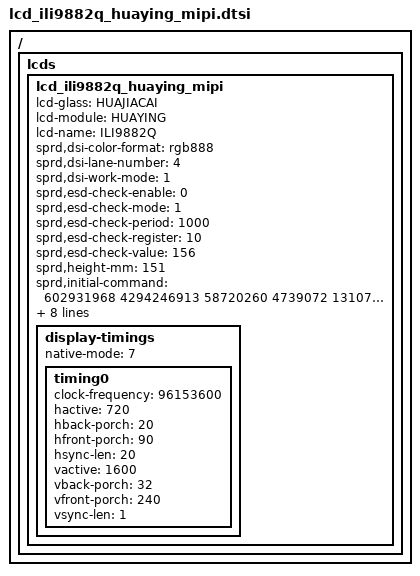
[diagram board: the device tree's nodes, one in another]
/ {
	fragment {
		target-path = "/";
		__overlay__ {
			lcds {
				lcd_ili9882q_huaying_mipi {
					lcd-glass = "HUAJIACAI";
					lcd-module = "HUAYING";
					lcd-name = "ILI9882Q";
					sprd,dsi-color-format = "rgb888";
					sprd,dsi-lane-number = <4>;
					sprd,dsi-work-mode = <1>;
					sprd,esd-check-enable = <0>;
					sprd,esd-check-mode = <1>;
					sprd,esd-check-period = <1000>;
					sprd,esd-check-register = <10>;
					sprd,esd-check-value = <156>;
					sprd,height-mm = <151>;
					sprd,initial-command = <602931968 4294246913 58720260 4739072 131073 58720260 33554464 131584 58720260 8947840 133128 58720260 10944512 133632 58720260 14090240 135680 58720260 16793600 135936 58720260 16842752 137216 58720260 17629184 139264 58720260 19922944 139520 58720260 20971520 138240 58720260 28966912 138752 58720260 29523968 141312 58720260 29729792 140032 58720260 30146560 142592 58720260 31195136 142848 58720260 32440320 142336 58720260 34209792 144896 58720260 34771968 142848 58720260 36241408 144896 58720260 36803584 144896 58720260 37220352 151552 58720260 41500672 144384 58720260 43078656 142848 58720260 44549120 144896 58720260 46127104 146432 58720260 47175680 151616 58720260 48320768 151552 58720260 50266112 151552 58720260 51224576 148992 58720260 53169920 146432 58720260 55115264 144896 58720260 57093120 151552 58720260 58141696 151552 58720260 59341824 152576 58720260 64226304 151040 58720260 65704320 151552 58720260 68157440 153088 58720260 71663616 151552 58720260 73142272 151552 58720260 74620416 151552 58720260 76100096 151552 58720260 77578240 153856 58720260 79056384 151616 58720260 80535936 152576 58720260 82015104 151552 58720260 83543712 151552 58720260 85022848 153088 58720260 86071360 150528 58720260 92371968 151552 58720260 95193344 121344 58720260 98014720 187413 10068113 195056 8390573 145408 9256399 150016 24696739 223682 38115729 298176 58822051 301620 157921281 167688 156797185 241381 147635457 162311 149732097 287255 141578241 160266 221197313 284799 172797441 275200 168465153 170497 168099585 285785 168124161 270479>;
					sprd,phy-bit-clock = <682296>;
					sprd,phy-escape-clock = <20000>;
					sprd,reset-on-sequence = <1 10 0 10 1 20>;
					sprd,sleep-in-command = <604348672 608174904 137216>;
					sprd,sleep-out-command = <608174904 286444660 146176>;
					sprd,width-mm = <68>;

					display-timings {
						native-mode = <7>;

						timing0 {
							clock-frequency = <96153600>;
							hactive = <720>;
							hback-porch = <20>;
							hfront-porch = <90>;
							hsync-len = <20>;
							vactive = <1600>;
							vback-porch = <32>;
							vfront-porch = <240>;
							vsync-len = <1>;
						};
					};
				};
			};
		};
	};
};

